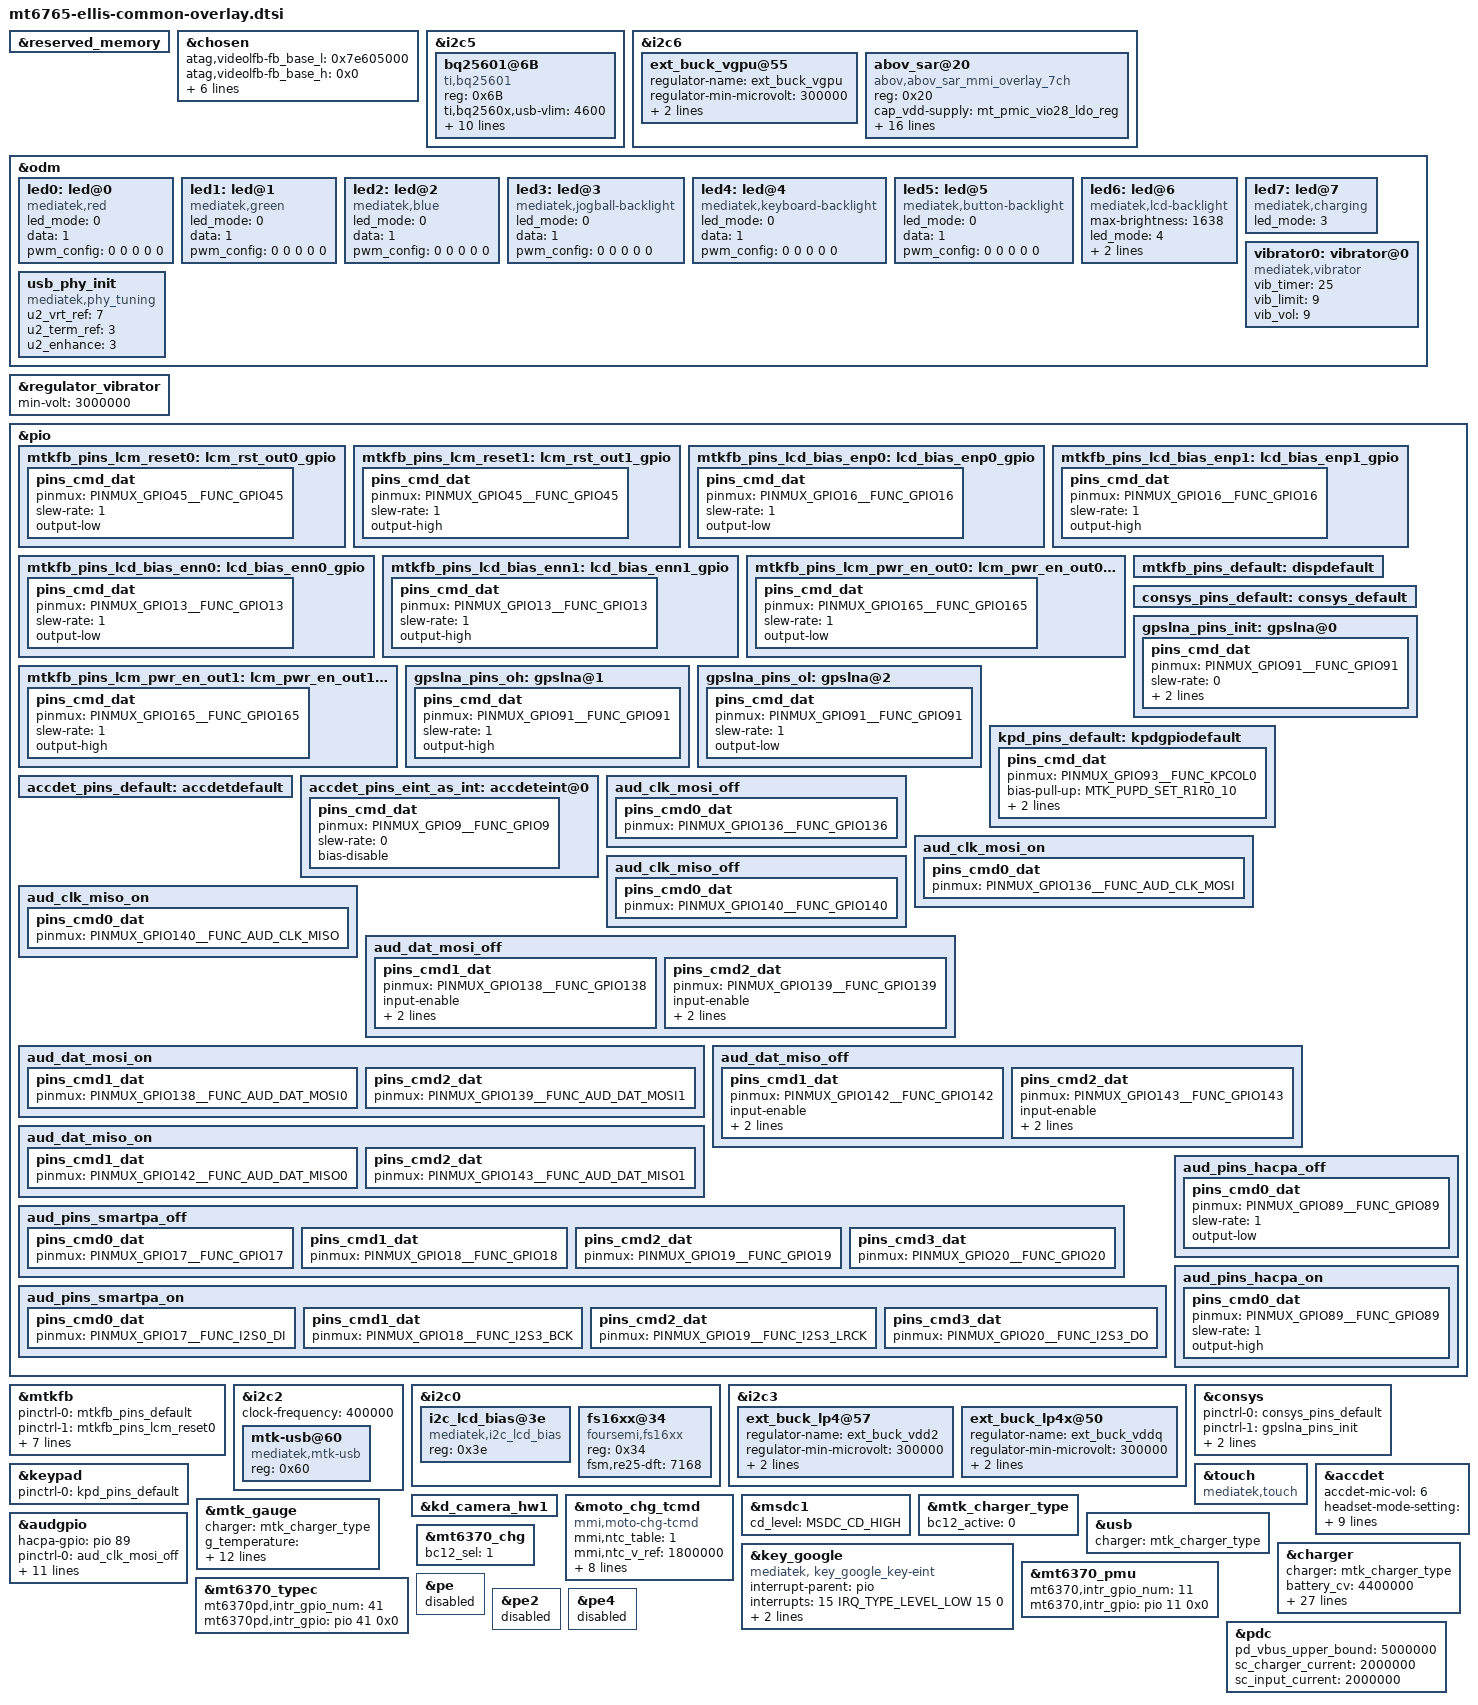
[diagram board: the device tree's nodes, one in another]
/* Copyright (c) 2020, The Linux Foundation. All rights reserved.
 *
 * This program is free software; you can redistribute it and/or modify
 * it under the terms of the GNU General Public License version 2 and
 * only version 2 as published by the Free Software Foundation.
 *
 * This program is distributed in the hope that it will be useful,
 * but WITHOUT ANY WARRANTY; without even the implied warranty of
 * MERCHANTABILITY or FITNESS FOR A PARTICULAR PURPOSE.  See the
 * GNU General Public License for more details.
 */

#include "mt6765-moto-common-overlay.dtsi"
//#include "mt6765-ellis-audio-overlay.dtsi"
//#include "mt6765-ellis-sensor-overlay.dtsi"
#include "mt6762-ellis-camera-sensor-overlay.dtsi"
#include "dt-bindings/mmc/mt6765-msdc.h"
#include "cust_mt6765_touch_ellis_720x1600.dtsi"

&reserved_memory {
};

/* chosen */
&chosen {
	/* fpga may has no lk, we need to specify display info here */
	/* fb buffer is reserved using this dts by memory node above */
	atag,videolfb-fb_base_l = <0x7e605000>;
	atag,videolfb-fb_base_h = <0x0>;
	atag,videolfb-islcmfound = <1>;
	atag,videolfb-islcm_inited = <0>;
	atag,videolfb-fps= <6000>;
	atag,videolfb-vramSize= <0x017e8000>;
	atag,videolfb-lcmname=
		"nt35695_fhd_dsi_cmd_truly_rt5081_drv";
};

&i2c5 {
	bq25601@6B {
		compatible = "ti,bq25601";
		reg = <0x6B>;
		ti,bq2560x,usb-vlim = <4600>;
		ti,bq2560x,usb-ilim = <2000>;
		ti,bq2560x,usb-vreg = <4400>;
		ti,bq2560x,usb-ichg = <2000>;
		ti,bq2560x,precharge-current = <256>;
		ti,bq2560x,termination-current = <180>;
		ti,bq2560x,boost-voltage = <4998>;
		ti,bq2560x,boost-current = <1200>;
		ti,bq2560x,enable_term;
		ti,bq2560x,stat-pin-ctrl = <3>;
		ti,bq2560x,vac-ovp-threshold = <6500>;

	};
};

&i2c6 {
    ext_buck_vgpu@55 {
        regulator-name ="ext_buck_vgpu";
        regulator-min-microvolt = <300000>;
        regulator-max-microvolt = <1300000>;
        vsel_pin = <2>;
    };
};

&odm {
	led0:led@0 {
		compatible = "mediatek,red";
		led_mode = <0>;
		data = <1>;
		pwm_config = <0 0 0 0 0>;
	};
	led1:led@1 {
		compatible = "mediatek,green";
		led_mode = <0>;
		data = <1>;
		pwm_config = <0 0 0 0 0>;
	};
	led2:led@2 {
		compatible = "mediatek,blue";
		led_mode = <0>;
		data = <1>;
		pwm_config = <0 0 0 0 0>;
	};
	led3:led@3 {
		compatible = "mediatek,jogball-backlight";
		led_mode = <0>;
		data = <1>;
		pwm_config = <0 0 0 0 0>;
	};
	led4:led@4 {
		compatible = "mediatek,keyboard-backlight";
		led_mode = <0>;
		data = <1>;
		pwm_config = <0 0 0 0 0>;
	};
	led5:led@5 {
		compatible = "mediatek,button-backlight";
		led_mode = <0>;
		data = <1>;
		pwm_config = <0 0 0 0 0>;
	};
	led6:led@6 {
		compatible = "mediatek,lcd-backlight";
		max-brightness = <1638>;
		led_mode = <4>;
		data = <1>;
		pwm_config = <0 1 0 0 0>;
	};
	led7:led@7 {
		compatible = "mediatek,charging";
		led_mode = <3>;
	};
	vibrator0:vibrator@0 {
		compatible = "mediatek,vibrator";
		vib_timer = <25>;
		vib_limit = <9>;
		vib_vol= <9>;
	};

        usb_phy_init:usb_phy_init {
		compatible = "mediatek,phy_tuning";
		u2_vrt_ref = <7>;
		u2_term_ref = <3>;
		u2_enhance = <3>;
		status = "okay";
	};
};

&regulator_vibrator {
       min-volt = <3000000>;//EKELLIS-59, yaocankun.wt, 20210407, update vibrator voltage
};

&pio {
	mtkfb_pins_lcm_reset0: lcm_rst_out0_gpio {
		pins_cmd_dat {
			pinmux = <PINMUX_GPIO45__FUNC_GPIO45>;
			slew-rate = <1>;
			output-low;
		};
	};

	mtkfb_pins_lcm_reset1: lcm_rst_out1_gpio {
		pins_cmd_dat {
			pinmux = <PINMUX_GPIO45__FUNC_GPIO45>;
			slew-rate = <1>;
			output-high;
		};
	};

	mtkfb_pins_lcd_bias_enp0: lcd_bias_enp0_gpio {
		pins_cmd_dat {
			pinmux = <PINMUX_GPIO16__FUNC_GPIO16>;
			slew-rate = <1>;
			output-low;
		};
	};

	mtkfb_pins_lcd_bias_enp1: lcd_bias_enp1_gpio {
		pins_cmd_dat {
			pinmux = <PINMUX_GPIO16__FUNC_GPIO16>;
			slew-rate = <1>;
			output-high;
		};
	};

	mtkfb_pins_lcd_bias_enn0: lcd_bias_enn0_gpio {
		pins_cmd_dat {
			pinmux = <PINMUX_GPIO13__FUNC_GPIO13>;
			slew-rate = <1>;
			output-low;
		};
	};

	mtkfb_pins_lcd_bias_enn1: lcd_bias_enn1_gpio {
		pins_cmd_dat {
			pinmux = <PINMUX_GPIO13__FUNC_GPIO13>;
			slew-rate = <1>;
			output-high;
		};
	};

	mtkfb_pins_lcm_pwr_en_out0: lcm_pwr_en_out0_gpio {
		pins_cmd_dat {
			pinmux = <PINMUX_GPIO165__FUNC_GPIO165>;
			slew-rate = <1>;
			output-low;
		};
	};

	mtkfb_pins_lcm_pwr_en_out1: lcm_pwr_en_out1_gpio {
		pins_cmd_dat {
			pinmux = <PINMUX_GPIO165__FUNC_GPIO165>;
			slew-rate = <1>;
			output-high;
		};
	};

	mtkfb_pins_default: dispdefault {
	};
};

&mtkfb {
	pinctrl-names = "dispdefault", "lcm_rst_out0_gpio", "lcm_rst_out1_gpio",
			"lcd_bias_enp0_gpio", "lcd_bias_enp1_gpio",
			"lcd_bias_enn0_gpio", "lcd_bias_enn1_gpio",
			"lcm_pwr_en_out0_gpio", "lcm_pwr_en_out1_gpio";
	pinctrl-0 = <&mtkfb_pins_default>;
	pinctrl-1 = <&mtkfb_pins_lcm_reset0>;
	pinctrl-2 = <&mtkfb_pins_lcm_reset1>;
	pinctrl-3 = <&mtkfb_pins_lcd_bias_enp0>;
	pinctrl-4 = <&mtkfb_pins_lcd_bias_enp1>;
	pinctrl-5 = <&mtkfb_pins_lcd_bias_enn0>;
	pinctrl-6 = <&mtkfb_pins_lcd_bias_enn1>;
	pinctrl-7 = <&mtkfb_pins_lcm_pwr_en_out0>;
	pinctrl-8 = <&mtkfb_pins_lcm_pwr_en_out1>;
	status = "okay";
};

&i2c2 {
	clock-frequency = <400000>;

	mtk-usb@60 {
		compatible = "mediatek,mtk-usb";
		reg = <0x60>;
		status = "okay";
	};
};

&i2c0 {
	i2c_lcd_bias@3e {
		compatible = "mediatek,i2c_lcd_bias";
		reg = <0x3e>;
		status = "okay";
	};

	fs16xx@34 {
		compatible = "foursemi,fs16xx";
		reg = <0x34>;
		fsm,re25-dft = <7168>;
		status = "okay";
	};
};

&i2c3 {
	ext_buck_lp4@57 {
		regulator-name ="ext_buck_vdd2";
		regulator-min-microvolt = <300000>;
		regulator-max-microvolt = <1300000>;
		vsel_pin = <0>;
	};

	ext_buck_lp4x@50 {
		regulator-name ="ext_buck_vddq";
		regulator-min-microvolt = <300000>;
		regulator-max-microvolt = <1300000>;
		vsel_pin = <1>;
	};
};

&i2c6 {
    status = "ok";
    abov_sar@20 {
        status = "ok";
        compatible = "abov,abov_sar_mmi_overlay_7ch";
        reg = <0x20>;
        cap_vdd-supply = <&mt_pmic_vio28_ldo_reg>;
        interrupt-parent = <&pio>;
        interrupts = <1 IRQ_TYPE_EDGE_FALLING 1 0>;
        abov,irq-gpio-std = <&pio 12 0>;
        reg_array_len = <0x03>;
        reg_array_val = <0x07 0x00 0x08 0x1F 0xFB 0x01>;
        cap,use_channel_ch0 = <0x00>;
        cap,use_channel_ch1 = <0x01>;
        cap,use_channel_ch2 = <0x02>;
        ch0_name = "capsense_bottom";
        ch1_name = "capsense_top_right";
        ch2_name = "capsense_top_left";
        label = "AbovCapSense";
        cap,channel_number = <0x03>;
        cap,fw_mode_ret = <0x39>;
        button_mask = <0x15>;
        cap,flash_erase_time = <1400>;
    };
};

/* CONSYS GPIO standardization */
&pio {
	consys_pins_default: consys_default {
	};
	gpslna_pins_init: gpslna@0 {
		pins_cmd_dat {
			pinmux = <PINMUX_GPIO91__FUNC_GPIO91>;
			slew-rate = <0>;
			bias-disable;
			output-low;
		};
	};
	gpslna_pins_oh: gpslna@1 {
		pins_cmd_dat {
			pinmux = <PINMUX_GPIO91__FUNC_GPIO91>;
			slew-rate = <1>;
			output-high;
		};
	};
	gpslna_pins_ol: gpslna@2 {
		pins_cmd_dat {
			pinmux = <PINMUX_GPIO91__FUNC_GPIO91>;
			slew-rate = <1>;
			output-low;
		};
	};
};
&consys {
	pinctrl-names = "default", "gps_lna_state_init",
		"gps_lna_state_oh", "gps_lna_state_ol";
	pinctrl-0 = <&consys_pins_default>;
	pinctrl-1 = <&gpslna_pins_init>;
	pinctrl-2 = <&gpslna_pins_oh>;
	pinctrl-3 = <&gpslna_pins_ol>;
	status = "okay";
};
/* CONSYS end */

&keypad {
	pinctrl-names = "default";
	pinctrl-0 = <&kpd_pins_default>;
};

&pio {
	kpd_pins_default: kpdgpiodefault {
		pins_cmd_dat {
			pinmux = <PINMUX_GPIO93__FUNC_KPCOL0>;
			bias-pull-up = <MTK_PUPD_SET_R1R0_10>;
			output-low;
			input-schmitt-enable;
		};
	};
};

&touch {
	compatible = "mediatek,touch";
};


/* accdet start */
&accdet {
	accdet-mic-vol = <6>;
	headset-mode-setting = <0x500 0x500 1 0x1f0 0x800 0x800 0x20 0x44>;
	accdet-plugout-debounce = <1>;
	accdet-mic-mode = <1>;
	headset-eint-level-pol = <8>;
	headset-three-key-threshold = <0 80 220 400>;
	headset-three-key-threshold-CDD = <0 121 192 600>;
	headset-four-key-threshold = <0 58 121 192 400>;
	pinctrl-names = "default", "state_eint_as_int";
	pinctrl-0 = <&accdet_pins_default>;
	pinctrl-1 = <&accdet_pins_eint_as_int>;
	status = "okay";
};
&pio {
	accdet_pins_default: accdetdefault {
	};
	accdet_pins_eint_as_int: accdeteint@0 {
		pins_cmd_dat {
			pinmux = <PINMUX_GPIO9__FUNC_GPIO9>;
			slew-rate = <0>;
			bias-disable;
		};
	};
};
/* accdet end */

/* CAMERA specify sensor */
&kd_camera_hw1 {

};
/* CAMERA specify sensor end */

&moto_chg_tcmd {
                compatible = "mmi,moto-chg-tcmd";
                status = "okay";

                mmi,ntc_table = <1>;
                mmi,ntc_v_ref = <1800000>;
                mmi,ntc_r_pull = <100000>;

                mmi,batid_v_ref = <1800000>;
                mmi,batid_r_pull = <100000>;

                mmi,adc-channel-cpu = <0>;
                mmi,adc-channel-charger = <2>;
                mmi,adc-channel-pa = <1>;
                mmi,adc-channel-batid = <3>;
                mmi,adc-channel-vbat = <100>;
};

/*
&bat_gm30 {
        io-channels = <&auxadc 5>;
        io-channel-names = "batteryID-channel";
        EMBEDDED_SEL = <(1)>;
        DIFFERENCE_FULLOCV_ITH = <(244)>;

        df-serialnum = "SB18C51711";
        #include "bat_setting/batterytable_kg40_atl_4000mah_ext.dtsi"
};

&mt_pmic_vtp_ldo_reg {
	regulator-min-microvolt = <3300000>;
	regulator-max-microvolt = <3300000>;
	regulator-boot-on;
	regulator-always-on;
};
*/

&msdc1 {
        cd_level = /bits/ 8 <MSDC_CD_HIGH>;
};

&mtk_charger_type {
        bc12_active = <0>;
};

&mtk_gauge {
	charger = <&mtk_charger_type>;
	/* battery prop */
	g_temperature = <(50) (25) (10) (0) (-10) (-25) (-30) (-35) (-40) (-45)>;

	g_FG_PSEUDO100 = <98 98 100 100
		98 98 100 100
		98 98 100 100
		98 98 100 100
		98 98 100 100
		100 100 100 100
		100 100 100 100
		100 100 100 100
		100 100 100 100
		100 100 100 100>;

	g_Q_MAX = <4075 3931 2490 1965
		4105 4001 2468 1984
		4209 3969 2310 1946
		4059 3974 1858 1873
		4011 3950 1843 1851
		2211 1652 1533 1541
		2201 1642 1523 1531
		2191 1632 1513 1521
		2181 1622 1503 1511
		2171 1612 1493 1501>;

	g_Q_MAX_H_CURRENT = <4075 3910 2190 1665
		4105 3971 2168 1684
		4209 3919 2010 1646
		4059 3781 1558 1573
		4011 3171 1543 1551
		2210 1650 1533 1541
		2200 1640 1523 1531
		2190 1630 1513 1521
		2180 1620 1503 1511
		2170 1610 1493 1501>;

	SHUTDOWN_1_TIME = <(7)>;

	ACTIVE_TABLE = <(5)>;

	//io-channels = <&auxadc 5>;
	//io-channel-names = "batteryID-channel";//TODO
        EMBEDDED_SEL = <(1)>;
        DIFFERENCE_FULLOCV_ITH = <(80)>;

	df-serialnum = "SB18D15207";
        #include "bat_setting/S96767AA1_ATL_4V4_4000MAH.dtsi"
        #include "bat_setting/S96767AA1_SUN_4V4_4000MAH.dtsi"
};

&usb {
        charger = <&mtk_charger_type>;
};

&key_google {
	compatible = "mediatek, key_google_key-eint";
	interrupt-parent = <&pio>;
	interrupts = <15 IRQ_TYPE_LEVEL_LOW 15 0>;
	deb-gpios = <&pio 15 0>;
	debounce = <64000>;
	status = "okay";
};

/* AUDIO GPIO standardization */
&audgpio {
	hacpa-gpio = <&pio 89 0x0>;
	pinctrl-names = "aud_clk_mosi_off",
			"aud_clk_mosi_on",
			"aud_clk_miso_off",
			"aud_clk_miso_on",
			"aud_dat_mosi_off",
			"aud_dat_mosi_on",
			"aud_dat_miso_off",
			"aud_dat_miso_on",
			"aud_smartpa_off",
			"aud_smartpa_on",
			"aud_pins_hacpa_off",
			"aud_pins_hacpa_on";
	pinctrl-0 = <&aud_clk_mosi_off>;
	pinctrl-1 = <&aud_clk_mosi_on>;
	pinctrl-2 = <&aud_clk_miso_off>;
	pinctrl-3 = <&aud_clk_miso_on>;
	pinctrl-4 = <&aud_dat_mosi_off>;
	pinctrl-5 = <&aud_dat_mosi_on>;
	pinctrl-6 = <&aud_dat_miso_off>;
	pinctrl-7 = <&aud_dat_miso_on>;
	pinctrl-8 = <&aud_pins_smartpa_off>;
	pinctrl-9 = <&aud_pins_smartpa_on>;
	pinctrl-10 = <&aud_pins_hacpa_off>;
	pinctrl-11 = <&aud_pins_hacpa_on>;
	status = "okay";
};

&pio {
	aud_clk_mosi_off: aud_clk_mosi_off {
		pins_cmd0_dat {
			pinmux = <PINMUX_GPIO136__FUNC_GPIO136>;
		};
	};

	aud_clk_mosi_on: aud_clk_mosi_on {
		pins_cmd0_dat {
			pinmux = <PINMUX_GPIO136__FUNC_AUD_CLK_MOSI>;
		};
	};

	aud_clk_miso_off: aud_clk_miso_off {
		pins_cmd0_dat {
			pinmux = <PINMUX_GPIO140__FUNC_GPIO140>;
		};
	};

	aud_clk_miso_on: aud_clk_miso_on {
		pins_cmd0_dat {
			pinmux = <PINMUX_GPIO140__FUNC_AUD_CLK_MISO>;
		};
	};

	aud_dat_mosi_off: aud_dat_mosi_off {
		pins_cmd1_dat {
			pinmux = <PINMUX_GPIO138__FUNC_GPIO138>;
			input-enable;
			slew-rate = <0>;
			bias-disable;
		};
		pins_cmd2_dat {
			pinmux = <PINMUX_GPIO139__FUNC_GPIO139>;
			input-enable;
			slew-rate = <0>;
			bias-disable;
		};
	};

	aud_dat_mosi_on: aud_dat_mosi_on {
		pins_cmd1_dat {
			pinmux = <PINMUX_GPIO138__FUNC_AUD_DAT_MOSI0>;
		};
		pins_cmd2_dat {
			pinmux = <PINMUX_GPIO139__FUNC_AUD_DAT_MOSI1>;
		};
	};

	aud_dat_miso_off: aud_dat_miso_off {
		pins_cmd1_dat {
			pinmux = <PINMUX_GPIO142__FUNC_GPIO142>;
			input-enable;
			slew-rate = <0>;
			bias-disable;
		};
		pins_cmd2_dat {
			pinmux = <PINMUX_GPIO143__FUNC_GPIO143>;
			input-enable;
			slew-rate = <0>;
			bias-disable;
		};
	};

	aud_dat_miso_on: aud_dat_miso_on {
		pins_cmd1_dat {
			pinmux = <PINMUX_GPIO142__FUNC_AUD_DAT_MISO0>;
		};
		pins_cmd2_dat {
			pinmux = <PINMUX_GPIO143__FUNC_AUD_DAT_MISO1>;
		};
	};

	aud_pins_smartpa_off: aud_pins_smartpa_off {
		pins_cmd0_dat {
			pinmux = <PINMUX_GPIO17__FUNC_GPIO17>;
		};
		pins_cmd1_dat {
			pinmux = <PINMUX_GPIO18__FUNC_GPIO18>;
		};
		pins_cmd2_dat {
			pinmux = <PINMUX_GPIO19__FUNC_GPIO19>;
		};
		pins_cmd3_dat {
			pinmux = <PINMUX_GPIO20__FUNC_GPIO20>;
		};
	};

	aud_pins_smartpa_on: aud_pins_smartpa_on {
		pins_cmd0_dat {
			pinmux = <PINMUX_GPIO17__FUNC_I2S0_DI>;
		};
		pins_cmd1_dat {
			pinmux = <PINMUX_GPIO18__FUNC_I2S3_BCK>;
		};
		pins_cmd2_dat {
			pinmux = <PINMUX_GPIO19__FUNC_I2S3_LRCK>;
		};
		pins_cmd3_dat {
			pinmux = <PINMUX_GPIO20__FUNC_I2S3_DO>;
		};
	};

	aud_pins_hacpa_off: aud_pins_hacpa_off {
		pins_cmd0_dat {
			pinmux = <PINMUX_GPIO89__FUNC_GPIO89>;
			slew-rate = <1>;
			output-low;
		};
	};

	aud_pins_hacpa_on: aud_pins_hacpa_on {
		pins_cmd0_dat {
			pinmux = <PINMUX_GPIO89__FUNC_GPIO89>;
			slew-rate = <1>;
			output-high;
		};
	};
};
/* AUDIO end */

&mt6370_pmu {
	mt6370,intr_gpio_num = <11>; /* direct defined GPIO num */
	mt6370,intr_gpio = <&pio 11 0x0>;
};

/*
&lk_charger {
	ac_charger_input_current = <2000000>;
	non_std_ac_charger_current = <500000>;
	charging_host_charger_current = <1500000>;
	ta_ac_charger_current = <2000000>;
};
*/

&charger {
	charger = <&mtk_charger_type>;
	/* common */
	battery_cv = <4400000>;
	max_charger_voltage = <6500000>;
	min_charger_voltage = <4600000>;

	/* charging current */
        usb_charger_current_suspend = <0>;
        usb_charger_current_unconfigured = <70000>;
        usb_charger_current_configured = <500000>;
	usb_charger_current = <500000>;
	ac_charger_current = <2000000>;
	ac_charger_input_current = <2000000>;
        non_std_ac_charger_current = <1000000>;
	charging_host_charger_current = <1500000>;
        apple_1_0a_charger_current = <650000>;
        apple_2_1a_charger_current = <800000>;
        ta_ac_charger_current = <2000000>;
        typec_limit_aicr = <2000000>;

        /* battery temperature protection */
        enable_min_charge_temperature;
        min_charge_temperature = <0>;
        min_charge_temperature_plus_x_degree = <10>;
        max_charge_temperature = <60>;
        max_charge_temperature_minus_x_degree = <45>;

        /*mmi config*/
        mmi,iterm-ma = <80>;
        mmi,mmi-temp-zones = <0 4200 804 0>,
                        <10 0 804 804>,
                        <15 4200 804 804>,
                        <45 0 3000 2800>,
                        <60 4200 2010 0>;
        mmi,enable-charging-limit;
        mmi,upper-limit-capacity = <65>;
        mmi,lower-limit-capacity = <60>;
        mmi,vfloat-comp-uv = <20000>;
};

&mt6370_typec {
	mt6370pd,intr_gpio_num = <41>; /* direct defined GPIO num */
	mt6370pd,intr_gpio = <&pio 41 0x0>;
};

&mt6370_chg {
	bc12_sel = <1>;
};

&pe {
	status = "disable";
};

&pe2 {
	status = "disable";
};

&pe4 {
	status = "disable";
};

&pdc {
	pd_vbus_upper_bound = <5000000>;
	sc_charger_current = <2000000>;
	sc_input_current = <2000000>;
};

#include "mt6765-moto-ellis-fps.dtsi"
/*End of this file, DO NOT ADD ANYTHING HERE*/
